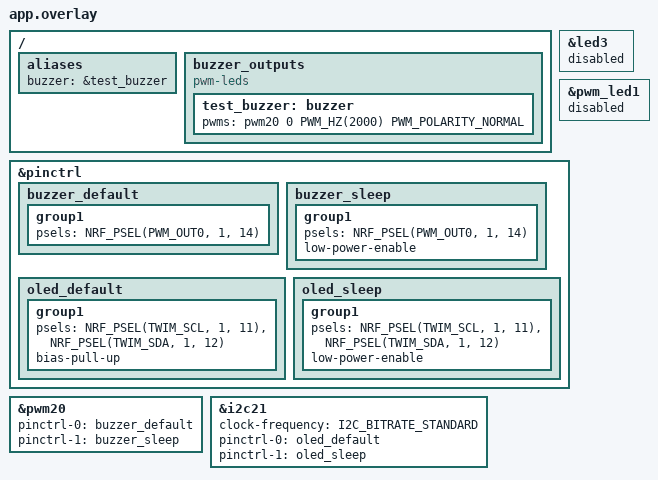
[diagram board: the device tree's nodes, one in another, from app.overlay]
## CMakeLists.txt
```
cmake_minimum_required(VERSION 3.20.0)
find_package(Zephyr REQUIRED HINTS $ENV{ZEPHYR_BASE})
project(techathon_waypoint_game)
target_sources(app PRIVATE src/main.c src/game.c src/route.c src/oled.c)
target_include_directories(app PRIVATE ../common)
target_link_libraries(app PRIVATE m)
```

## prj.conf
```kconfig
CONFIG_BT=y
CONFIG_BT_OBSERVER=y
CONFIG_BT_DEVICE_NAME="Techathon waypoints"
CONFIG_GPIO=y
CONFIG_PWM=y
CONFIG_I2C=y
CONFIG_PRINTK=y
CONFIG_CBPRINTF_FP_SUPPORT=y
CONFIG_MAIN_STACK_SIZE=3072
```

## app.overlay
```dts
#include <zephyr/dt-bindings/pinctrl/nrf-pinctrl.h>
#include <zephyr/dt-bindings/pwm/pwm.h>

/ {
    aliases {
        buzzer = &test_buzzer;
    };
    buzzer_outputs {
        compatible = "pwm-leds";
        test_buzzer: buzzer {
            pwms = <&pwm20 0 PWM_HZ(2000) PWM_POLARITY_NORMAL>;
        };
    };
};

/* P1.14 is also wired to LED3 on the DK. Do not claim it as a GPIO LED. */
&led3 {
    status = "disabled";
};
/* Remove the board's default PWM LED consumer of PWM20 channel 0. */
&pwm_led1 {
    status = "disabled";
};

&pinctrl {
    buzzer_default: buzzer_default {
        group1 {
            psels = <NRF_PSEL(PWM_OUT0, 1, 14)>;
        };
    };
    buzzer_sleep: buzzer_sleep {
        group1 {
            psels = <NRF_PSEL(PWM_OUT0, 1, 14)>;
            low-power-enable;
        };
    };
};

&pwm20 {
    status = "okay";
    pinctrl-0 = <&buzzer_default>;
    pinctrl-1 = <&buzzer_sleep>;
    pinctrl-names = "default", "sleep";
};

#include <zephyr/dt-bindings/pinctrl/nrf-pinctrl.h>
#include <zephyr/dt-bindings/i2c/i2c.h>

&pinctrl {
    oled_default: oled_default {
        group1 {
            psels = <NRF_PSEL(TWIM_SCL, 1, 11)>,
                    <NRF_PSEL(TWIM_SDA, 1, 12)>;
            bias-pull-up;
        };
    };
    oled_sleep: oled_sleep {
        group1 {
            psels = <NRF_PSEL(TWIM_SCL, 1, 11)>,
                    <NRF_PSEL(TWIM_SDA, 1, 12)>;
            low-power-enable;
        };
    };
};

&i2c21 {
    status = "okay";
    clock-frequency = <I2C_BITRATE_STANDARD>;
    pinctrl-0 = <&oled_default>;
    pinctrl-1 = <&oled_sleep>;
    pinctrl-names = "default", "sleep";
};
```

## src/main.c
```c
#include <zephyr/kernel.h>
#include <zephyr/bluetooth/bluetooth.h>
#include <zephyr/drivers/gpio.h>
#include <zephyr/drivers/pwm.h>
#include <zephyr/sys/atomic.h>
#include <zephyr/sys/printk.h>
#include <math.h>
#include <string.h>
#include "beacon.h"
#include "proximity.h"
#include "button_filter.h"
#include "game.h"
#include "oled.h"

#define BEEP_ON_MS 60
#define BEEP_PERIOD PWM_HZ(2000)

static const struct gpio_dt_spec buttons[] = {
    GPIO_DT_SPEC_GET(DT_ALIAS(sw2), gpios), /* A = Button 2 */
    GPIO_DT_SPEC_GET(DT_ALIAS(sw0), gpios), /* B = Button 0 */
    GPIO_DT_SPEC_GET(DT_ALIAS(sw3), gpios), /* C = Button 3 */
    GPIO_DT_SPEC_GET(DT_ALIAS(sw1), gpios), /* D = Button 1 */
};
static const struct pwm_dt_spec buzzer = PWM_DT_SPEC_GET(DT_ALIAS(buzzer));
K_MUTEX_DEFINE(receiver_lock);
static struct proximity received;
static size_t receiver_target;
static atomic_t display_ready;
static atomic_t displayed_revision;
K_MSGQ_DEFINE(display_queue, sizeof(struct display_frame), 1, 4);

/* The display has its own thread: I2C transfers cannot delay button polling
 * or stretch beep timing. Only this thread owns the OLED framebuffer/bus. */
static void display_loop(void *a, void *b, void *c)
{
    ARG_UNUSED(a); ARG_UNUSED(b); ARG_UNUSED(c);
    struct display_frame view;
    int64_t retry_at = 0;
    for (;;) {
        k_msgq_get(&display_queue, &view, K_FOREVER);
        if (!atomic_get(&display_ready)) {
            if (k_uptime_get() < retry_at) { continue; }
            int err = oled_init();
            if (err) {
                printk("OLED unavailable (%d); check P1.11/P1.12 and 3.3 V\n", err);
                retry_at = k_uptime_get() + 5000;
                continue;
            }
            atomic_set(&display_ready, 1);
        }
        int err = oled_render(&view);
        if (err) {
            printk("OLED write failed: %d\n", err);
            atomic_clear(&display_ready);
            retry_at = k_uptime_get() + 5000;
        } else {
            atomic_set(&displayed_revision, view.revision);
        }
    }
}
K_THREAD_DEFINE(oled_thread, 2048, display_loop, NULL, NULL, NULL, 7, 0, 0);

static bool parse_field(struct bt_data *data, void *user_data)
{
    if (data->type != BT_DATA_MANUFACTURER_DATA) { return true; }
    struct beacon_identity id;
    if (!beacon_decode(data->data, data->data_len, &id)) { return true; }
    k_mutex_lock(&receiver_lock, K_FOREVER);
    bool matches = receiver_target < route_count &&
                   waypoint_matches(&route[receiver_target], &id);
    if (matches) {
        proximity_update(&received, *(int8_t *)user_data, id.power_at_1m, k_uptime_get());
    }
    k_mutex_unlock(&receiver_lock);
    return !matches;
}

static void device_found(const bt_addr_le_t *addr, int8_t rssi,
                         uint8_t adv_type, struct net_buf_simple *ad)
{
    ARG_UNUSED(addr);
    if (adv_type == BT_GAP_ADV_TYPE_ADV_NONCONN_IND) {
        bt_data_parse(ad, parse_field, &rssi);
    }
}

static void select_target(size_t target)
{
    k_mutex_lock(&receiver_lock, K_FOREVER);
    receiver_target = target;
    memset(&received, 0, sizeof(received));
    k_mutex_unlock(&receiver_lock);
    if (target < route_count) {
        printk("Target %u/%u: %s, major=%u minor=%u\n", (unsigned)target + 1,
               (unsigned)route_count, route[target].label, route[target].major,
               route[target].minor);
    }
}

static int read_buttons(uint8_t *mask)
{
    *mask = 0;
    for (unsigned i = 0; i < ARRAY_SIZE(buttons); ++i) {
        int active = gpio_pin_get_dt(&buttons[i]);
        if (active < 0) { return active; }
        if (active) { *mask |= 1U << i; }
    }
    return 0;
}

static void make_view(struct display_frame *v, const struct game *g,
                      const struct observation *o, int64_t now)
{
    memset(v, 0, sizeof(*v));
    v->state = g->state;
    v->audio_enabled = g->audio_enabled;
    snprintk(v->progress, sizeof(v->progress), "%u/%u",
             (unsigned)MIN(g->target + 1, g->count), (unsigned)g->count);
    const struct waypoint *w = g->target < g->count ? &g->waypoints[g->target] : NULL;
    snprintk(v->label, sizeof(v->label), "%s", w ? w->label : "JELLING");
    if (g->state == WELCOME) {
        snprintk(v->label, sizeof(v->label), "JELLING");
        snprintk(v->progress, sizeof(v->progress), "0/%u", (unsigned)g->count);
        snprintk(v->status, sizeof(v->status), "WELCOME");
        snprintk(v->detail, sizeof(v->detail), "%s",
                 g->audio_enabled ? "AUDIO - ON" : "AUDIO - OFF");
    } else if (g->state == NAVIGATING) {
        const char *names[] = {"SEARCHING", "FAR", "NEAR", "CLOSE"};
        snprintk(v->status, sizeof(v->status), "%s", names[g->band]);
        v->search_position = (now / 200) % 10;
        if (g->band == SEARCHING) {
            snprintk(v->detail, sizeof(v->detail), "%s",
                     o->fresh ? "ACQUIRING SIGNAL" : "FINDING BEACON...");
        } else {
            unsigned cm = MIN((unsigned)(MIN(o->metres, 999.99f) * 100.0f), 99999U);
            if (g->touch_ready) {
                snprintk(v->detail, sizeof(v->detail), "EST %u.%02uM D TOUCH",
                         cm / 100U, cm % 100U);
            } else {
                snprintk(v->detail, sizeof(v->detail), "EST %u.%02uM",
                         cm / 100U, cm % 100U);
            }
            v->bars = g->band == CLOSE ? 10 : g->band == NEAR ? 6 : 2;
        }
    } else if (g->state == QUESTION) {
        for (unsigned i = 0; i < 2; ++i) {
            snprintk(v->question[i], sizeof(v->question[i]), "%s", w->question[i]);
        }
        for (unsigned i = 0; i < 4; ++i) {
            snprintk(v->answers[i], sizeof(v->answers[i]), "%s", w->answers[i]);
        }
    } else if (g->state == ANSWER_RIGHT || g->state == ANSWER_WRONG) {
        bool correct = g->state == ANSWER_RIGHT;
        snprintk(v->status, sizeof(v->status), "%s", correct ? "CORRECT" : "WRONG");
        snprintk(v->detail, sizeof(v->detail), "%c - %s", 'A' + g->selected_answer,
                 correct ? "NEXT WAYPOINT" : "TRY AGAIN");
        v->bars = correct ? 10 : 0;
    } else if (g->state == ROUTE_COMPLETE) {
        snprintk(v->status, sizeof(v->status), "ALL DONE");
        snprintk(v->detail, sizeof(v->detail), "ROUTE COMPLETE");
        v->bars = 10;
    } else {
        snprintk(v->status, sizeof(v->status), "CONFIG");
        snprintk(v->detail, sizeof(v->detail), "CHECK ROUTE SETTINGS");
    }
}

/* Nonblocking tone scheduler: 60 ms fixed-pitch bursts with a band-based gap. */
static int update_buzzer(int gap, int64_t now)
{
    static bool sounding;
    static int previous_gap = -1;
    static int64_t deadline;
    int err;
    if (gap != previous_gap) {
        err = pwm_set_dt(&buzzer, BEEP_PERIOD, 0);
        if (err) { return err; }
        sounding = false;
        previous_gap = gap;
        deadline = now;
    }
    if (gap < 0 || now < deadline) { return 0; }
    sounding = !sounding;
    err = pwm_set_dt(&buzzer, BEEP_PERIOD, sounding ? BEEP_PERIOD / 2U : 0);
    deadline = now + (sounding ? BEEP_ON_MS : gap);
    return err;
}

int main(void)
{
    struct game game;
    struct button_filter filter = {0};
    game_init(&game, route, route_count);
    if (!pwm_is_ready_dt(&buzzer) || pwm_set_dt(&buzzer, BEEP_PERIOD, 0)) {
        printk("Buzzer initialization failed\n");
        return 0;
    }
    for (unsigned i = 0; i < ARRAY_SIZE(buttons); ++i) {
        if (!gpio_is_ready_dt(&buttons[i]) ||
            gpio_pin_configure_dt(&buttons[i], GPIO_INPUT)) {
            printk("Button %u initialization failed\n", i);
            return 0;
        }
    }
    if (game.state != CONFIG_ERROR) {
        select_target(0);
        int err = bt_enable(NULL);
        if (err) { printk("Bluetooth initialization failed: %d\n", err); return 0; }
        const struct bt_le_scan_param scan = {
            .type = BT_LE_SCAN_TYPE_PASSIVE, .options = BT_LE_SCAN_OPT_NONE,
            .interval = 0x00a0, .window = 0x00a0,
        };
        err = bt_le_scan_start(&scan, device_found);
        if (err) { printk("Scan start failed: %d\n", err); return 0; }
    }
    printk("Live waypoint game. B2=A, B0=B, B3=C, B1=D.\n");
    int64_t next_display = 0, next_log = 0;
    enum game_state previous_state = CONFIG_ERROR;
    enum proximity_band previous_band = SEARCHING;
    bool previous_audio = game.audio_enabled;
    uint32_t feedback_revision = 1;
    for (;;) {
        int64_t now = k_uptime_get();
        struct proximity p;
        k_mutex_lock(&receiver_lock, K_FOREVER);
        p = received;
        k_mutex_unlock(&receiver_lock);
        struct observation o = {
            .fresh = proximity_fresh(&p, now),
            .touch_fresh = proximity_fresh(&p, now) && now - p.last_seen_ms <= 1000,
            .samples = p.samples,
        };
        if (o.fresh && game.target < game.count) {
            o.metres = powf(10.0f, (p.power_at_1m - p.filtered_rssi) /
                           (10.0f * game.waypoints[game.target].path_loss_exponent));
        }
        uint8_t raw;
        int err = read_buttons(&raw);
        if (err) {
            (void)pwm_set_dt(&buzzer, BEEP_PERIOD, 0);
            printk("Button read failed: %d\n", err);
            return 0;
        }
        uint8_t pressed = button_filter_update(&filter, raw, now);
        size_t old_target = game.target;
        bool screen_current = atomic_get(&display_ready) &&
                              (uint32_t)atomic_get(&displayed_revision) == feedback_revision;
        game_step(&game, &o, screen_current ? pressed : 0, now);
        if (game.target != old_target) {
            select_target(game.target);
            memset(&o, 0, sizeof(o));
        }
        bool feedback_changed = game.state != previous_state || game.band != previous_band ||
                                game.audio_enabled != previous_audio;
        if (feedback_changed) { ++feedback_revision; }
        screen_current = atomic_get(&display_ready) &&
                         (uint32_t)atomic_get(&displayed_revision) == feedback_revision;
        /* Start a new cadence only after its matching OLED frame is on screen. */
        err = update_buzzer(screen_current ? game_beep_gap_ms(&game) : -1, now);
        if (err) {
            (void)pwm_set_dt(&buzzer, BEEP_PERIOD, 0);
            printk("Buzzer failed: %d\n", err);
            return 0;
        }
        if (now >= next_display || feedback_changed) {
            struct display_frame view;
            make_view(&view, &game, &o, now);
            view.revision = feedback_revision;
            /* Coalesce updates: never block the 20 ms input/tone loop. */
            while (k_msgq_put(&display_queue, &view, K_NO_WAIT)) { k_msgq_purge(&display_queue); }
            next_display = now + 200;
        }
        if (game.state != previous_state || now >= next_log) {
            printk("state=%d target=%u band=%d ready=%d RSSI=%.1f estimated=%.2fm fresh=%d\n",
                   game.state, (unsigned)game.target + 1, game.band, game.touch_ready,
                   (double)p.filtered_rssi, (double)o.metres, o.fresh);
            next_log = now + 2000;
        }
        previous_state = game.state;
        previous_band = game.band;
        previous_audio = game.audio_enabled;
        k_msleep(20);
    }
}
```

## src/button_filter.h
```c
#ifndef WAYPOINT_BUTTON_FILTER_H
#define WAYPOINT_BUTTON_FILTER_H
#include <stdbool.h>
#include <stdint.h>
struct button_filter {
    uint8_t raw, stable;
    int64_t changed_at;
    bool armed;
};
/* Poll at 20 ms. One event per press; chords require release and are ignored. */
static inline uint8_t button_filter_update(struct button_filter *b, uint8_t raw, int64_t now)
{
    if (raw != b->raw) { b->raw = raw; b->changed_at = now; }
    if (now - b->changed_at < 40) { return 0; }
    if (raw == 0) { b->stable = 0; b->armed = true; return 0; }
    if (raw == b->stable) { return 0; }
    b->stable = raw;
    bool armed = b->armed;
    b->armed = false;
    return armed && !(raw & (raw - 1U)) ? raw : 0;
}
#endif
```

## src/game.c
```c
#include "game.h"
#include <math.h>
#include <string.h>

#define BAND_DWELL_MS 500
#define CLOSE_DWELL_MS 1000
#define RESULT_MS 1500

static void reset_navigation(struct game *g)
{
    g->state = NAVIGATING;
    g->band = g->candidate = SEARCHING;
    g->close_since = -1;
    g->touch_ready = false;
}

void game_init(struct game *g, const struct waypoint *items, size_t count)
{
    memset(g, 0, sizeof(*g));
    g->waypoints = items;
    g->count = count;
    g->selected_answer = -1;
    g->audio_enabled = true;
    reset_navigation(g);
    g->state = route_valid(items, count) ? WELCOME : CONFIG_ERROR;
}

static enum proximity_band desired_band(enum proximity_band current, float m)
{
    /* Entry/exit thresholds differ to prevent chatter around boundaries. */
    if (current == CLOSE && m <= 1.8f) { return CLOSE; }
    if (m <= 1.5f) { return CLOSE; }
    if (current == FAR && m >= 4.5f) { return FAR; }
    if (current == NEAR && m <= 5.5f) { return NEAR; }
    return m >= 5.0f ? FAR : NEAR;
}

void game_step(struct game *g, const struct observation *o, uint8_t pressed, int64_t now)
{
    if (g->state == CONFIG_ERROR) { return; }
    if (g->state != QUESTION && pressed == 2U) {
        g->audio_enabled = !g->audio_enabled;
        return;
    }
    if (g->state == ROUTE_COMPLETE) { return; }
    if (g->state == WELCOME) {
        if (pressed == 1U) { reset_navigation(g); }
        return;
    }
    if (g->state == ANSWER_RIGHT || g->state == ANSWER_WRONG) {
        if (now < g->result_until) { return; }
        if (g->state == ANSWER_WRONG) { g->state = QUESTION; return; }
        if (++g->target == g->count) { g->state = ROUTE_COMPLETE; return; }
        reset_navigation(g);
        return; /* Never apply the old target's observation to the new target. */
    }
    if (g->state == QUESTION) {
        for (unsigned i = 0; i < 4; ++i) {
            if (pressed != (1U << i)) { continue; }
            g->selected_answer = (int)i;
            g->state = i == g->waypoints[g->target].correct_answer ?
                       ANSWER_RIGHT : ANSWER_WRONG;
            g->result_until = now + RESULT_MS;
            return;
        }
        return;
    }
    g->touch_ready = false;
    if (!o->fresh || o->samples < 5 || !isfinite(o->metres) || o->metres <= 0) {
        g->band = g->candidate = SEARCHING;
        g->close_since = -1;
        return;
    }
    enum proximity_band wanted = desired_band(g->band, o->metres);
    if (wanted != g->candidate) {
        g->candidate = wanted;
        g->candidate_since = now;
    }
    if (wanted != g->band && now - g->candidate_since >= BAND_DWELL_MS) {
        g->band = wanted;
    }
    /* Leaving the close region revokes eligibility immediately, even during dwell. */
    if (g->band != CLOSE || wanted != CLOSE || !o->touch_fresh) {
        g->close_since = -1;
    } else {
        if (g->close_since < 0) { g->close_since = now; }
        g->touch_ready = now - g->close_since >= CLOSE_DWELL_MS;
    }
    if (g->touch_ready && pressed == 8U) {
        g->state = QUESTION;
        g->touch_ready = false;
    }
}

int game_beep_gap_ms(const struct game *g)
{
    if (!g->audio_enabled || g->state != NAVIGATING) { return -1; }
    switch (g->band) {
    case FAR: return 1000;
    case NEAR: return 400;
    case CLOSE: return 100;
    default: return -1;
    }
}
```

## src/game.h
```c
#ifndef WAYPOINT_GAME_H
#define WAYPOINT_GAME_H
#include <stdbool.h>
#include <stdint.h>
#include "route.h"

enum game_state { WELCOME, NAVIGATING, QUESTION, ANSWER_RIGHT, ANSWER_WRONG,
                  ROUTE_COMPLETE, CONFIG_ERROR };
enum proximity_band { SEARCHING, FAR, NEAR, CLOSE };
struct observation {
    bool fresh;          /* Matching packet within the 5-second lost timeout. */
    bool touch_fresh;    /* Matching packet within the last 1 second. */
    unsigned samples;
    float metres;
};
struct game {
    enum game_state state;
    enum proximity_band band, candidate;
    const struct waypoint *waypoints;
    size_t count, target;
    int64_t candidate_since, close_since, result_until;
    bool touch_ready;
    bool audio_enabled;
    int selected_answer;
};
void game_init(struct game *g, const struct waypoint *items, size_t count);
/* pressed is a debounced, release-armed bitmask: bit 0=A, 1=B, 2=C, 3=D. */
void game_step(struct game *g, const struct observation *o, uint8_t pressed, int64_t now);
int game_beep_gap_ms(const struct game *g); /* -1 = silent */
#endif
```

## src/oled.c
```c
/* SSD1315 128x64, four-pin I2C module; pixels stored in page order. */
#include <zephyr/kernel.h>
#include <zephyr/device.h>
#include <zephyr/drivers/i2c.h>
#include <zephyr/sys/printk.h>
#include <errno.h>
#include <stdbool.h>
#include <stdint.h>
#include <string.h>
#include "oled.h"

static const struct device *const bus = DEVICE_DT_GET(DT_NODELABEL(i2c21));
static uint8_t address;

static int command(uint8_t value)
{
    uint8_t packet[] = {0x00, value};
    return i2c_write(bus, packet, sizeof(packet), address);
}

/* One page is eight pixels high. Send in small chunks for EasyDMA. */
static int write_page(uint8_t page, const uint8_t pixels[128])
{
    int err = command(0xB0 | page);
    if (!err) { err = command(0x00); }
    if (!err) { err = command(0x10); }
    for (int x = 0; x < 128 && !err; x += 16) {
        uint8_t packet[17] = {0x40};
        memcpy(packet + 1, pixels + x, 16);
        err = i2c_write(bus, packet, sizeof(packet), address);
    }
    return err;
}

static uint8_t frame[8][128];

/* 5x7 uppercase and numeric glyphs, columns with the top pixel in bit 0. */
static const uint8_t letters[26][5] = {
 {0x7e,0x11,0x11,0x11,0x7e}, {0x7f,0x49,0x49,0x49,0x36},
 {0x3e,0x41,0x41,0x41,0x22}, {0x7f,0x41,0x41,0x22,0x1c},
 {0x7f,0x49,0x49,0x49,0x41}, {0x7f,0x09,0x09,0x09,0x01},
 {0x3e,0x41,0x49,0x49,0x7a}, {0x7f,0x08,0x08,0x08,0x7f},
 {0x00,0x41,0x7f,0x41,0x00}, {0x20,0x40,0x41,0x3f,0x01},
 {0x7f,0x08,0x14,0x22,0x41}, {0x7f,0x40,0x40,0x40,0x40},
 {0x7f,0x02,0x0c,0x02,0x7f}, {0x7f,0x04,0x08,0x10,0x7f},
 {0x3e,0x41,0x41,0x41,0x3e}, {0x7f,0x09,0x09,0x09,0x06},
 {0x3e,0x41,0x51,0x21,0x5e}, {0x7f,0x09,0x19,0x29,0x46},
 {0x46,0x49,0x49,0x49,0x31}, {0x01,0x01,0x7f,0x01,0x01},
 {0x3f,0x40,0x40,0x40,0x3f}, {0x1f,0x20,0x40,0x20,0x1f},
 {0x3f,0x40,0x38,0x40,0x3f}, {0x63,0x14,0x08,0x14,0x63},
 {0x07,0x08,0x70,0x08,0x07}, {0x61,0x51,0x49,0x45,0x43}
};
static const uint8_t digits[10][5] = {
 {0x3e,0x51,0x49,0x45,0x3e}, {0x00,0x42,0x7f,0x40,0x00},
 {0x42,0x61,0x51,0x49,0x46}, {0x21,0x41,0x45,0x4b,0x31},
 {0x18,0x14,0x12,0x7f,0x10}, {0x27,0x45,0x45,0x45,0x39},
 {0x3c,0x4a,0x49,0x49,0x30}, {0x01,0x71,0x09,0x05,0x03},
 {0x36,0x49,0x49,0x49,0x36}, {0x06,0x49,0x49,0x29,0x1e}
};

static void pixel(int x, int y)
{
    if (x >= 0 && x < 128 && y >= 0 && y < 64) {
        frame[y / 8][x] |= 1U << (y % 8);
    }
}

static void text(int x, int y, const char *str, int scale)
{
    for (; *str; ++str, x += 6 * scale) {
        for (int col = 0; col < 5; ++col) {
            uint8_t bits = 0;
            if (*str >= 'A' && *str <= 'Z') { bits = letters[*str - 'A'][col]; }
            else if (*str >= '0' && *str <= '9') { bits = digits[*str - '0'][col]; }
            else if (*str == '-') { bits = 0x08; }
            else if (*str == '?') { const uint8_t g[] = {2,1,81,9,6}; bits = g[col]; }
            else if (*str == '/') { const uint8_t g[] = {32,16,8,4,2}; bits = g[col]; }
            else if (*str == '.') { bits = col == 2 ? 0x60 : 0; }
            for (int row = 0; row < 7; ++row) {
                if (!(bits & (1U << row))) { continue; }
                for (int dx = 0; dx < scale; ++dx) {
                    for (int dy = 0; dy < scale; ++dy) {
                        pixel(x + col * scale + dx, y + row * scale + dy);
                    }
                }
            }
        }
    }
}

int oled_render(const struct display_frame *view)
{
    memset(frame, 0, sizeof(frame));
    text(4, 1, view->label, 1);
    text(72, 1, view->audio_enabled ? "SND" : "MUTE", 1);
    text(104, 1, view->progress, 1);
    for (int x = 4; x < 124; ++x) { pixel(x, 10); }
    if (view->state == WELCOME) {
        text(4, 14, view->status, 2);
        text(4, 33, view->detail, 1);
        text(4, 44, "A - START GAME", 1);
        text(4, 54, "B - TOGGLE AUDIO", 1);
    } else if (view->state == QUESTION) {
        text(4, 13, view->question[0], 1);
        text(4, 22, view->question[1], 1);
        char option[12];
        for (int i = 0; i < 4; ++i) {
            snprintk(option, sizeof(option), "%c %s", 'A' + i, view->answers[i]);
            text(i % 2 ? 68 : 4, i < 2 ? 34 : 44, option, 1);
        }
        text(4, 56, "A  B  C  D TO ANSWER", 1);
    } else {
        text(4, 17, view->status, 2);
        text(4, 36, view->detail, 1);
        for (int i = 0; i < 10; ++i) {
            bool filled = view->state == NAVIGATING && !strcmp(view->status, "SEARCHING") ?
                          i == view->search_position : i < view->bars;
            for (int x = 0; x < 9; ++x) {
                for (int y = 0; y < 14; ++y) {
                    if (filled || x == 0 || x == 8 || y == 0 || y == 13) {
                        pixel(4 + i * 12 + x, 49 + y);
                    }
                }
            }
        }
    }
    for (uint8_t page = 0; page < 8; ++page) {
        int err = write_page(page, frame[page]);
        if (err) { return err; }
    }
    return 0;
}

int oled_init(void)
{
    if (!device_is_ready(bus)) {
        printk("I2C controller not ready\n");
        return -ENODEV;
    }
    k_msleep(100);

    /* Detect either standard 7-bit SSD1315 address using display-off. */
    address = 0x3C;
    if (command(0xAE)) {
        address = 0x3D;
        if (command(0xAE)) {
            printk("No OLED at 0x3C/0x3D. Check power, SDA and SCL.\n");
            return -ENODEV;
        }
    }
    printk("OLED responding at 0x%02x\n", address);

    static const uint8_t init[] = {
        0xAE,             /* Display off */
        0xD5, 0x80,       /* Clock */
        0xA8, 0x3F,       /* 64 rows */
        0xD3, 0x00,       /* Display offset */
        0x40,             /* Start line zero */
        0x8D, 0x14,       /* Internal charge pump */
        0x20, 0x02,       /* Page addressing */
        0xA1, 0xC8,       /* Segment / COM direction */
        0xDA, 0x12,       /* COM configuration for 128x64 */
        0x81, 0x7F,       /* Moderate contrast */
        0xAD, 0x10,       /* SSD1315 internal current reference, 150 uA max */
        0xD9, 0xF1,       /* Precharge */
        0xDB, 0x20,       /* VCOMH */
        0xA4, 0xA6,       /* Show RAM, normal polarity */
    };
    for (size_t i = 0; i < sizeof(init); ++i) {
        int err = command(init[i]);
        if (err) {
            printk("OLED initialization failed: %d\n", err);
            return -ENODEV;
        }
    }

    /* Clear old RAM before enabling the panel. */
    memset(frame, 0, sizeof(frame));
    for (uint8_t page = 0; page < 8; ++page) {
        int err = write_page(page, frame[page]);
        if (err) { return err; }
    }
    return command(0xAF);
}
```

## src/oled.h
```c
#ifndef WAYPOINT_OLED_H
#define WAYPOINT_OLED_H
#include "game.h"
struct display_frame {
    enum game_state state;
    uint32_t revision;
    char label[15], progress[8], status[10], detail[21];
    char question[2][21], answers[4][9];
    uint8_t bars, search_position;
    bool audio_enabled;
};
int oled_init(void);
int oled_render(const struct display_frame *view);
#endif
```

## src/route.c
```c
#include "route.h"
#include <math.h>
#include <string.h>

/* Ordered route: IDs match our ESP32-C3 beacon minors (1..7).
 * Add or reorder entries here; route_count is derived automatically. */
const struct waypoint route[] = {
    {
        .label = "STATION 01", .uuid = BEACON_UUID_BYTES,
        .major = BEACON_MAJOR, .minor = 1,
        .question = {"HARALD BLUETOOTH", "BORN AROUND?"},
        .answers = {"810 AD", "910 AD", "1066 AD", "1200 AD"},
        .correct_answer = 1, .path_loss_exponent = 2.0f,
    },
    {
        .label = "STATION 02", .uuid = BEACON_UUID_BYTES,
        .major = BEACON_MAJOR, .minor = 2,
        .question = {"PAGAN VIKING BURIAL", "MOST COMMON WAY?"},
        .answers = {"CREMATED", "CHURCHES", "CAVES", "SEA SHIP"},
        .correct_answer = 0, .path_loss_exponent = 2.0f,
    },
    {
        .label = "STATION 03", .uuid = BEACON_UUID_BYTES,
        .major = BEACON_MAJOR, .minor = 3,
        .question = {"HARALDS BIGGEST", "RING FORTRESS?"},
        .answers = {"TRELBORG", "FYRKAT", "NONNEBKN", "AGGERSBG"},
        .correct_answer = 3, .path_loss_exponent = 2.0f,
    },
    {
        .label = "STATION 04", .uuid = BEACON_UUID_BYTES,
        .major = BEACON_MAJOR, .minor = 4,
        .question = {"HOW TO ENTER", "VALHALLA IN MYTH?"},
        .answers = {"OLD AGE", "BATTLE", "AT SEA", "ILLNESS"},
        .correct_answer = 1, .path_loss_exponent = 2.0f,
    },
    {
        .label = "STATION 05", .uuid = BEACON_UUID_BYTES,
        .major = BEACON_MAJOR, .minor = 5,
        .question = {"NAME OF GOD THORS", "MAGICAL HAMMER?"},
        .answers = {"GUNGNIR", "MJOLNIR", "GRAM", "DRAUPNIR"},
        .correct_answer = 1, .path_loss_exponent = 2.0f,
    },
    {
        .label = "STATION 06", .uuid = BEACON_UUID_BYTES,
        .major = BEACON_MAJOR, .minor = 6,
        .question = {"RAINBOW BRIDGE FROM", "MIDGARD TO ASGARD?"},
        .answers = {"YGGDRASL", "GJALLAR", "BIFROST", "FENRIR"},
        .correct_answer = 2, .path_loss_exponent = 2.0f,
    },
    {
        .label = "STATION 07", .uuid = BEACON_UUID_BYTES,
        .major = BEACON_MAJOR, .minor = 7,
        .question = {"FIRST RECORDED KING", "ON JELLING STONE?"},
        .answers = {"GORM", "HARALD", "SWEYN", "CANUTE"},
        .correct_answer = 0, .path_loss_exponent = 2.0f,
    },
};
const size_t route_count = sizeof(route) / sizeof(route[0]);

bool waypoint_matches(const struct waypoint *target, const struct beacon_identity *id)
{
    return !memcmp(target->uuid, id->uuid, 16) && target->major == id->major &&
           target->minor == id->minor;
}

static bool printable(const char *s, size_t limit)
{
    if (!s || !*s || strlen(s) > limit) { return false; }
    for (; *s; ++s) {
        if (!((*s >= 'A' && *s <= 'Z') || (*s >= '0' && *s <= '9') ||
              *s == ' ' || *s == '?' || *s == '-' || *s == '.')) { return false; }
    }
    return true;
}

bool route_valid(const struct waypoint *items, size_t count)
{
    if (!items || count < 1 || count > 9) { return false; }
    for (size_t i = 0; i < count; ++i) {
        const struct waypoint *w = &items[i];
        if (!printable(w->label, 14) || !printable(w->question[0], 20) ||
            !printable(w->question[1], 20) || w->correct_answer > 3 ||
            !isfinite(w->path_loss_exponent) || w->path_loss_exponent <= 0) {
            return false;
        }
        for (int a = 0; a < 4; ++a) {
            if (!printable(w->answers[a], 8)) { return false; }
        }
        for (size_t j = 0; j < i; ++j) {
            if (!memcmp(items[j].uuid, w->uuid, 16) && items[j].major == w->major &&
                items[j].minor == w->minor) { return false; }
        }
    }
    return true;
}
```

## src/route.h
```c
#ifndef WAYPOINT_ROUTE_H
#define WAYPOINT_ROUTE_H
#include <stdbool.h>
#include <stddef.h>
#include "beacon.h"

struct waypoint {
    const char *label;            /* At most 14 uppercase characters. */
    uint8_t uuid[16];
    uint16_t major;
    uint16_t minor;
    const char *question[2];      /* At most 20 characters per line. */
    const char *answers[4];       /* At most 8 characters each. */
    unsigned correct_answer;     /* A=0, B=1, C=2, D=3. */
    float path_loss_exponent;
};
extern const struct waypoint route[];
extern const size_t route_count;
bool route_valid(const struct waypoint *items, size_t count);
bool waypoint_matches(const struct waypoint *target, const struct beacon_identity *id);
#endif
```
